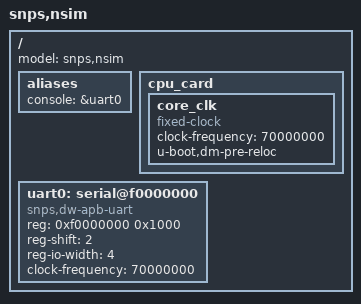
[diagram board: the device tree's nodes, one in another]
// SPDX-License-Identifier: GPL-2.0+
/*
 * Copyright (C) 2015-2016, 2020 Synopsys, Inc. (www.synopsys.com)
 */
/dts-v1/;

#include "skeleton.dtsi"

/ {
	model = "snps,nsim";

	aliases {
		console = &uart0;
	};

	cpu_card {
		core_clk: core_clk {
			#clock-cells = <0>;
			compatible = "fixed-clock";
			clock-frequency = <70000000>;
			u-boot,dm-pre-reloc;
		};
	};

	uart0: serial@f0000000 {
		compatible = "snps,dw-apb-uart";
		reg = <0xf0000000 0x1000>;
		reg-shift = <2>;
		reg-io-width = <4>;
		clock-frequency = <70000000>;
	};

};
